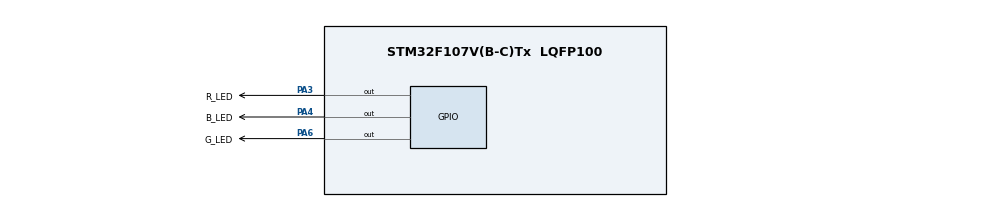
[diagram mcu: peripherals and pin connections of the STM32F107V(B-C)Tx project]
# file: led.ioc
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Mcu.Family=STM32F1
Mcu.Name=STM32F107V(B-C)Tx
Mcu.Package=LQFP100
NVIC.PriorityGroup=NVIC_PRIORITYGROUP_4
PA13.Mode=JTAG_5_pins
PA13.Signal=SYS_JTMS-SWDIO
PA14.Mode=JTAG_5_pins
PA14.Signal=SYS_JTCK-SWCLK
PA15.Mode=JTAG_5_pins
PA15.Signal=SYS_JTDI
PA3.GPIO_Label=R_LED
PA3.Signal=GPIO_Output
PA4.GPIO_Label=B_LED
PA4.Signal=GPIO_Output
PA6.GPIO_Label=G_LED
PA6.Signal=GPIO_Output
PB3.Mode=JTAG_5_pins
PB3.Signal=SYS_JTDO
PB4.Mode=JTAG_5_pins
PB4.Signal=SYS_NJTRST
ProjectManager.HeapSize=0x200
ProjectManager.StackSize=0x400
ProjectManager.TargetToolchain=STM32CubeIDE
RCC.USBFreq_Value=10666666.666666666
board=custom

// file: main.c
/* USER CODE BEGIN Header */
/**
  ******************************************************************************
  * @file           : main.c
  * @brief          : Main program body
  ******************************************************************************
  * @attention
  *
  * <h2><center>&copy; Copyright (c) 2021 STMicroelectronics.
  * All rights reserved.</center></h2>
  *
  * This software component is licensed by ST under BSD 3-Clause license,
  * the "License"; You may not use this file except in compliance with the
  * License. You may obtain a copy of the License at:
  *                        opensource.org/licenses/BSD-3-Clause
  *
  ******************************************************************************
  */
/* USER CODE END Header */
#include "main.h"
#include "gpio.h"

void SystemClock_Config(void);

/* USER CODE BEGIN 0 */
enum
{
	RED=0,
	GREEN=1,
	BLUE=2
};

void RGB_LED_ctl(uint8_t color)
{
	switch(color)
	{
	case RED:
		HAL_GPIO_WritePin(B_LED_GPIO_Port, B_LED_Pin, GPIO_PIN_SET);
		HAL_GPIO_WritePin(G_LED_GPIO_Port, G_LED_Pin, GPIO_PIN_SET);
		HAL_GPIO_WritePin(R_LED_GPIO_Port, R_LED_Pin, GPIO_PIN_RESET);
		break;

	case GREEN:
		HAL_GPIO_WritePin(B_LED_GPIO_Port, B_LED_Pin, GPIO_PIN_SET);
		HAL_GPIO_WritePin(G_LED_GPIO_Port, G_LED_Pin, GPIO_PIN_RESET);
		HAL_GPIO_WritePin(R_LED_GPIO_Port, R_LED_Pin, GPIO_PIN_SET);
		break;

	case BLUE:
		HAL_GPIO_WritePin(B_LED_GPIO_Port, B_LED_Pin, GPIO_PIN_RESET);
		HAL_GPIO_WritePin(G_LED_GPIO_Port, G_LED_Pin, GPIO_PIN_SET);
		HAL_GPIO_WritePin(R_LED_GPIO_Port, R_LED_Pin, GPIO_PIN_SET);
		break;
	}
	HAL_Delay(100);
}
/* USER CODE END 0 */

int main(void)
{

  /* MCU Configuration--------------------------------------------------------*/

  /* Reset of all peripherals, Initializes the Flash interface and the Systick. */
  HAL_Init();

  /* Configure the system clock */
  SystemClock_Config();

  /* Initialize all configured peripherals */
  MX_GPIO_Init();

  /* Infinite loop */
  while (1)
  {

    /* USER CODE BEGIN 3 */
		RGB_LED_ctl(GREEN);
		RGB_LED_ctl(RED);
		RGB_LED_ctl(BLUE);
  }
  /* USER CODE END 3 */
}

void SystemClock_Config(void)
{
  RCC_OscInitTypeDef RCC_OscInitStruct = {0};
  RCC_ClkInitTypeDef RCC_ClkInitStruct = {0};

  /** Initializes the RCC Oscillators according to the specified parameters
  * in the RCC_OscInitTypeDef structure.
  */
  RCC_OscInitStruct.OscillatorType = RCC_OSCILLATORTYPE_HSI;
  RCC_OscInitStruct.HSIState = RCC_HSI_ON;
  RCC_OscInitStruct.HSICalibrationValue = RCC_HSICALIBRATION_DEFAULT;
  RCC_OscInitStruct.PLL.PLLState = RCC_PLL_NONE;
  RCC_OscInitStruct.PLL2.PLL2State = RCC_PLL_NONE;
  if (HAL_RCC_OscConfig(&RCC_OscInitStruct) != HAL_OK)
  {
    Error_Handler();
  }
  /** Initializes the CPU, AHB and APB buses clocks
  */
  RCC_ClkInitStruct.ClockType = RCC_CLOCKTYPE_HCLK|RCC_CLOCKTYPE_SYSCLK
                              |RCC_CLOCKTYPE_PCLK1|RCC_CLOCKTYPE_PCLK2;
  RCC_ClkInitStruct.SYSCLKSource = RCC_SYSCLKSOURCE_HSI;
  RCC_ClkInitStruct.AHBCLKDivider = RCC_SYSCLK_DIV1;
  RCC_ClkInitStruct.APB1CLKDivider = RCC_HCLK_DIV1;
  RCC_ClkInitStruct.APB2CLKDivider = RCC_HCLK_DIV1;

  if (HAL_RCC_ClockConfig(&RCC_ClkInitStruct, FLASH_LATENCY_0) != HAL_OK)
  {
    Error_Handler();
  }
  /** Configure the Systick interrupt time
  */
  __HAL_RCC_PLLI2S_ENABLE();
}

void Error_Handler(void)
{
  __disable_irq();
  while (1)
  {
  }
}

/************************ (C) COPYRIGHT STMicroelectronics *****END OF FILE****/
